# PIC32CM5164LS00048 register map
Vendor: Microchip Technology; Series: PIC32CMLS00; File version: 0
CPU: CM23 r0p0, selectable endian, MPU, no FPU, 2 interrupt priority bits
Registers are 32-bit, read-write, reset 0x0 unless marked. A register's access mark holds for its fields unless they carry their own. Offsets are from the block's base; [hi:lo] are bit positions.

## NVMCTRL — Non-Volatile Memory Controller
Base 0x41004000; register names take the prefix NVMCTRL_
Same registers: NVMCTRL_SEC 0x41005000 (register names take the prefix NVMCTRL_SEC_)
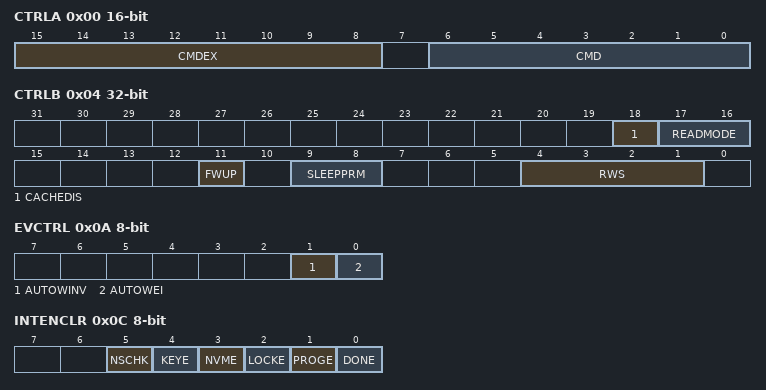
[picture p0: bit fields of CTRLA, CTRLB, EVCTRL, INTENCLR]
0x00 CTRLA 16-bit wo — Control A
  [15:8] CMDEX — Command Execution
    165=KEY (Execution Key)
  [6:0] CMD — Command
    2=ER (Erase Row - Erases the row addressed by the ADDR register.); 4=WP (Write Page - Writes the contents of the page buffer to the page addressed by the ADDR register.); 66=SPRM (Sets the power reduction mode.); 67=CPRM (Clears the power reduction mode.); 68=PBC (Page Buffer Clear - Clears the page buffer.); 70=INVALL (Invalidate all cache lines.); 75=SDAL0 (Set DAL=0); 76=SDAL1 (Set DAL=1); 77=SDAL2 (Set DAL=2)
0x04 CTRLB — Control B
  [18] CACHEDIS — Cache Disable
  [17:16] READMODE — NVMCTRL Read Mode
    0=NO_MISS_PENALTY (The NVM Controller (cache system) does not insert wait states on a cache miss. Gives the best system performance.); 1=LOW_POWER (Reduces power consumption of the cache system, but inserts a wait state each time there is a cache miss. This mode may not be relevant if CPU performance is required, as the application will be stalled and may lead to increase run time.); 2=DETERMINISTIC (The cache system ensures that a cache hit or miss takes the same amount of time, determined by the number of programmed flash wait states. This mode can be used for real-time applications that require deterministic execution timings.)
  [11] FWUP — fast wake-up
  [9:8] SLEEPPRM — Power Reduction Mode during Sleep
    0=WAKEONACCESS (NVM block enters low-power mode when entering sleep.NVM block exits low-power mode upon first access.); 1=WAKEUPINSTANT (NVM block enters low-power mode when entering sleep.NVM block exits low-power mode when exiting sleep.); 3=DISABLED (Auto power reduction disabled.)
  [4:1] RWS — NVM Read Wait States
0x08 CTRLC 8-bit reset 0x1 — Control C
  [0] MANW — Manual Write
0x0A EVCTRL 8-bit — Event Control
  [1] AUTOWINV — Auto Write Event Polarity Inverted
  [0] AUTOWEI — Auto Write Event Enable
0x0C INTENCLR 8-bit — Interrupt Enable Clear
  [5] NSCHK — NS configuration change detected Interrupt Clear
  [4] KEYE — Key Write Error Interrupt Clear
  [3] NVME — NVM Error Interrupt Clear
  [2] LOCKE — Lock Error Status Interrupt Clear
  [1] PROGE — Programming Error Status Interrupt Clear
  [0] DONE — NVM Done Interrupt Clear
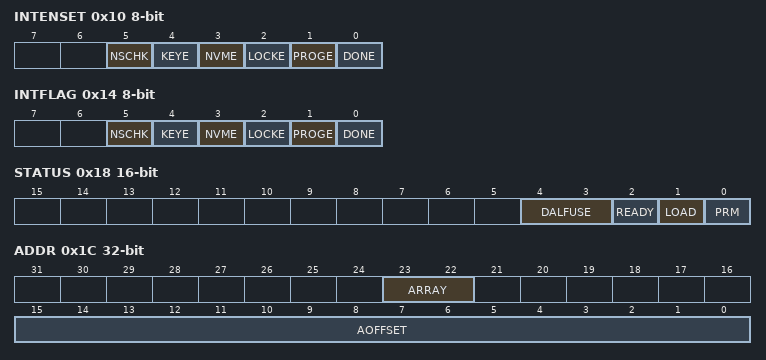
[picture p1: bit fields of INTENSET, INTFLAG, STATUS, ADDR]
0x10 INTENSET 8-bit — Interrupt Enable Set
  [5] NSCHK — NS configuration change detected Interrupt Enable
  [4] KEYE — Key Write Error Interrupt Enable
  [3] NVME — NVM Error Interrupt Enable
  [2] LOCKE — Lock Error Status Interrupt Enable
  [1] PROGE — Programming Error Status Interrupt Enable
  [0] DONE — NVM Done Interrupt Enable
0x14 INTFLAG 8-bit — Interrupt Flag Status and Clear
  [5] NSCHK — NS configuration change detected
  [4] KEYE — KEY Write Error
  [3] NVME — NVM Error
  [2] LOCKE — Lock Error Status
  [1] PROGE — Programming Error Status
  [0] DONE — NVM Done
0x18 STATUS 16-bit ro
  [4:3] DALFUSE — Debug Access Level Fuse
    0=DAL0 (Access to very limited features); 1=DAL1 (Access to all non-secure memory. Can debug non-secure CPU code); 2=DAL2 (Access to all memory. Can debug secure and non-secure CPU code)
  [2] READY — NVM Ready
  [1] LOAD — NVM Page Buffer Active Loading
  [0] PRM — Power Reduction Mode
0x1C ADDR — Address
  [23:22] ARRAY — Array Select
    0=FLASH; 1=DATAFLASH; 2=NVMROWS (NVM Configuration Rows)
  [15:0] AOFFSET — NVM Address Offset In The Selected Array
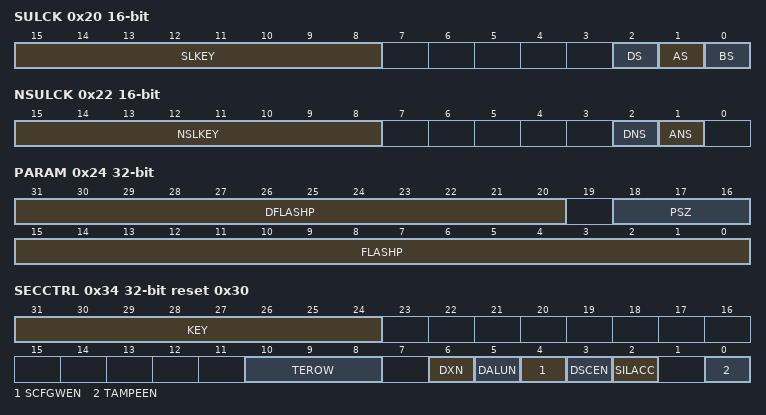
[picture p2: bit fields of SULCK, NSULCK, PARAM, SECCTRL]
0x20 SULCK 16-bit — Secure Unlock Register
  [15:8] SLKEY — Write Key
    165=KEY (Write Key)
  [2] DS — Secure Data Flash (DS Region)
  [1] AS — Secure Flash (AS Region)
  [0] BS — Secure Flash (BOOTPROT/BS Region)
0x22 NSULCK 16-bit — Non-Secure Unlock Register
  [15:8] NSLKEY — Write Key
    165=KEY (Write Key)
  [2] DNS — Non-Secure Data Flash (DNS Region)
  [1] ANS — Non-Secure Flash (ANS Region)
0x24 PARAM — NVM Parameter
  [31:20] DFLASHP — DATAFLASH Pages
  [18:16] PSZ — Page Size
    0=8 bytes; 1=16 bytes; 2=32 bytes; 3=64 bytes; 4=128 bytes; 5=256 bytes; 6=512 bytes; 7=1024 bytes
  [15:0] FLASHP — FLASH Pages
0x30 DSCC wo — Data Scramble Configuration
  [29:0] DSCKEY — Data Scramble Key
0x34 SECCTRL reset 0x30 — Security Control
  [31:24] KEY — Write Key
    165=KEY (Write Key)
  [10:8] TEROW — Tamper Rease Row
  [6] DXN — Data Flash is eXecute Never
  [5] DALUN — DAL unlock
  [4] SCFGWEN — Security Configuration Write Enable
  [3] DSCEN — Data Scramble Enable
  [2] SILACC — Silent Access
  [0] TAMPEEN — Tamper Erase Enable
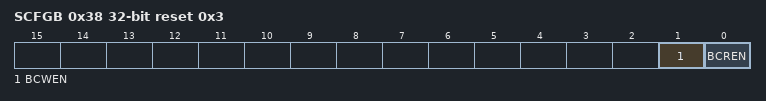
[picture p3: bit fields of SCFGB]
0x38 SCFGB reset 0x3 — Secure Boot Configuration
  [1] BCWEN — Boot Configuration Row Write Enable
  [0] BCREN — Boot Configuration Row Read Enable
0x3C SCFGAD reset 0x1 — Secure Application and Data Configuration
  [0] URWEN — User Row Write Enable
0x40 NONSEC reset 0x1 — Non-secure Write Enable
  [0] WRITE — Non-secure APB alias write enable, non-secure AHB writes to non-secure regions enable
0x44 NSCHK reset 0x1 — Non-secure Write Reference Value
  [0] WRITE — Reference value to be checked against NONSEC.WRITE

## Notices in the file
Copyright (c) 2017 Microchip Technology Inc.
SPDX-License-Identifier: Apache-2.0
Licensed under the Apache License, Version 2.0 (the "License");
you may not use this file except in compliance with the License.
You may obtain a copy of the License at
http://www.apache.org/licenses/LICENSE-2.0
Unless required by applicable law or agreed to in writing, software
distributed under the License is distributed on an "AS IS" BASIS,
WITHOUT WARRANTIES OR CONDITIONS OF ANY KIND, either express or implied.
See the License for the specific language governing permissions and
limitations under the License.
